# BL808 register map
File version: 0.1
Registers are access not given, no defined reset value unless marked. A register's access mark holds for its fields unless they carry their own. Offsets are from the block's base; [hi:lo] are bit positions.

## CODEC_MISC
Base 0x30020000
0x00 codec_bus_ctrl
  [15:0] rg_pclk_force_on rw
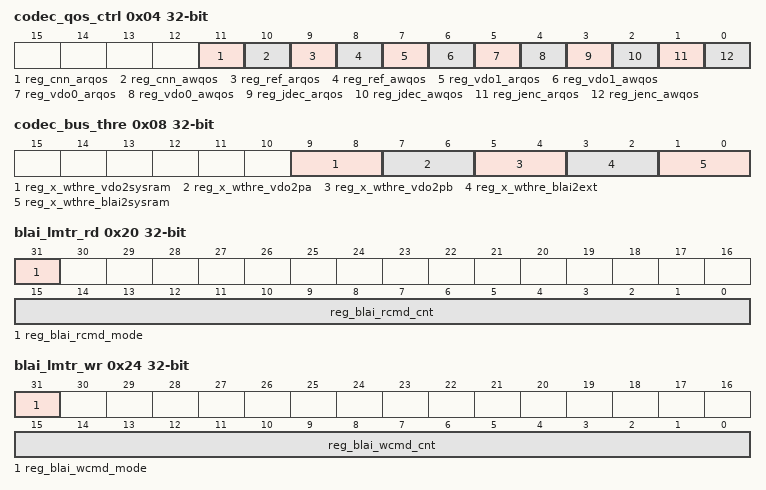
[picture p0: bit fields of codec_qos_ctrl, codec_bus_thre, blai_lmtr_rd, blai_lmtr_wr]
0x04 codec_qos_ctrl
  [11] reg_cnn_arqos rw, [10] reg_cnn_awqos rw, [9] reg_ref_arqos rw, [8] reg_ref_awqos rw, [7] reg_vdo1_arqos rw, [6] reg_vdo1_awqos rw, [5] reg_vdo0_arqos rw, [4] reg_vdo0_awqos rw, [3] reg_jdec_arqos rw, [2] reg_jdec_awqos rw, [1] reg_jenc_arqos rw, [0] reg_jenc_awqos rw
0x08 codec_bus_thre
  [9:8] reg_x_wthre_vdo2sysram rw, [7:6] reg_x_wthre_vdo2pa rw, [5:4] reg_x_wthre_vdo2pb rw, [3:2] reg_x_wthre_blai2ext rw, [1:0] reg_x_wthre_blai2sysram rw
0x20 blai_lmtr_rd
  [31] reg_blai_rcmd_mode rw, [15:0] reg_blai_rcmd_cnt rw
0x24 blai_lmtr_wr
  [31] reg_blai_wcmd_mode rw, [15:0] reg_blai_wcmd_cnt rw
0x28 id_selection
  [0] rg_jenc_id_sel rw
0xFC CODEC_MISC_Dummy rw
  [31:0] dummy_reg

## MIPI
Base 0x3001A000
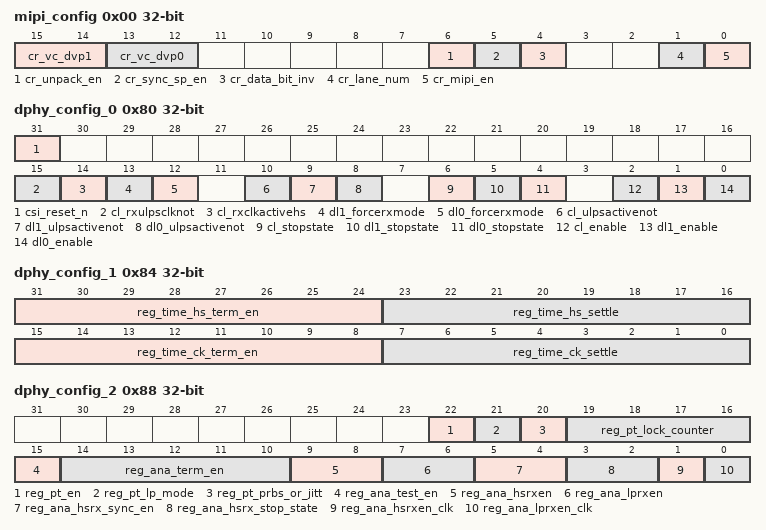
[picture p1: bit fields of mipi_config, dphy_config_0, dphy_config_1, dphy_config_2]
0x00 mipi_config
  [15:14] cr_vc_dvp1 rw, [13:12] cr_vc_dvp0 rw, [6] cr_unpack_en rw, [5] cr_sync_sp_en rw, [4] cr_data_bit_inv rw, [1] cr_lane_num rw, [0] cr_mipi_en rw
0x04 mipi_int_status
  [3:0] mipi_int_status ro
0x08 mipi_int_mask
  [3:0] mipi_int_mask rw
0x0C mipi_int_clear
  [3:0] mipi_int_clear write-once
0x20 gnr_buf_status
  [3:0] st_gnr_fifo_cnt ro
0x24 gnr_buf_rdata ro
  [31:0] gnr_buf_rdata
0x80 dphy_config_0
  [31] csi_reset_n rw, [15] cl_rxulpsclknot ro, [14] cl_rxclkactivehs ro, [13] dl1_forcerxmode rw, [12] dl0_forcerxmode rw, [10] cl_ulpsactivenot ro, [9] dl1_ulpsactivenot ro, [8] dl0_ulpsactivenot ro, [6] cl_stopstate ro, [5] dl1_stopstate ro, [4] dl0_stopstate ro, [2] cl_enable rw, [1] dl1_enable rw, [0] dl0_enable rw
0x84 dphy_config_1 rw
  [31:24] reg_time_hs_term_en, [23:16] reg_time_hs_settle, [15:8] reg_time_ck_term_en, [7:0] reg_time_ck_settle
0x88 dphy_config_2
  [22] reg_pt_en rw, [21] reg_pt_lp_mode rw, [20] reg_pt_prbs_or_jitt rw, [19:16] reg_pt_lock_counter rw, [15] reg_ana_test_en rw, [14:10] reg_ana_term_en rw, [9:8] reg_ana_hsrxen rw, [7:6] reg_ana_lprxen rw, [5:4] reg_ana_hsrx_sync_en rw, [3:2] reg_ana_hsrx_stop_state rw, [1] reg_ana_hsrxen_clk rw, [0] reg_ana_lprxen_clk rw
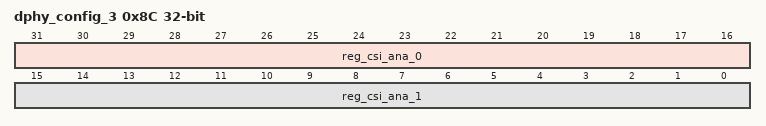
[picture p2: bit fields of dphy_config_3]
0x8C dphy_config_3 rw
  [31:16] reg_csi_ana_0, [15:0] reg_csi_ana_1
0xFC dummy_reg rw
  [31:0] dummy_reg

## OSD_A_BLEND_LAYER0
Base 0x30013000
Same registers: OSD_A_BLEND_LAYER1 0x30013100, OSD_A_BLEND_LAYER2 0x30013200, OSD_A_BLEND_LAYER3 0x30013300, OSD_B_BLEND_LAYER0 0x30014000, OSD_B_BLEND_LAYER1 0x30014100, OSD_DP_BLEND_LAYER0 0x30015000, OSD_DP_BLEND_LAYER1 0x30015100, OSD_DP_BLEND_LAYER2 0x30015200, OSD_DP_BLEND_LAYER3 0x30015300
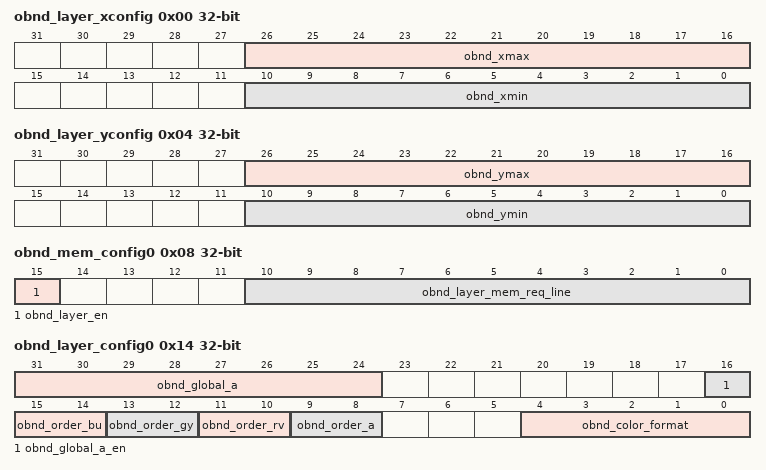
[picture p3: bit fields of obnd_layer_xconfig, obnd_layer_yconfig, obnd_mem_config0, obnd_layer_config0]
0x00 obnd_layer_xconfig
  [26:16] obnd_xmax rw, [10:0] obnd_xmin rw
0x04 obnd_layer_yconfig
  [26:16] obnd_ymax rw, [10:0] obnd_ymin rw
0x08 obnd_mem_config0
  [15] obnd_layer_en rw, [10:0] obnd_layer_mem_req_line rw
0x0C obnd_mem_config1 rw
  [31:0] obnd_mem_addr
0x10 obnd_mem_config2 rw
  [31:0] obnd_mem_dw_cnt
0x14 obnd_layer_config0
  [31:24] obnd_global_a rw, [16] obnd_global_a_en rw, [15:14] obnd_order_bu rw, [13:12] obnd_order_gy rw, [11:10] obnd_order_rv rw, [9:8] obnd_order_a rw, [4:0] obnd_color_format rw
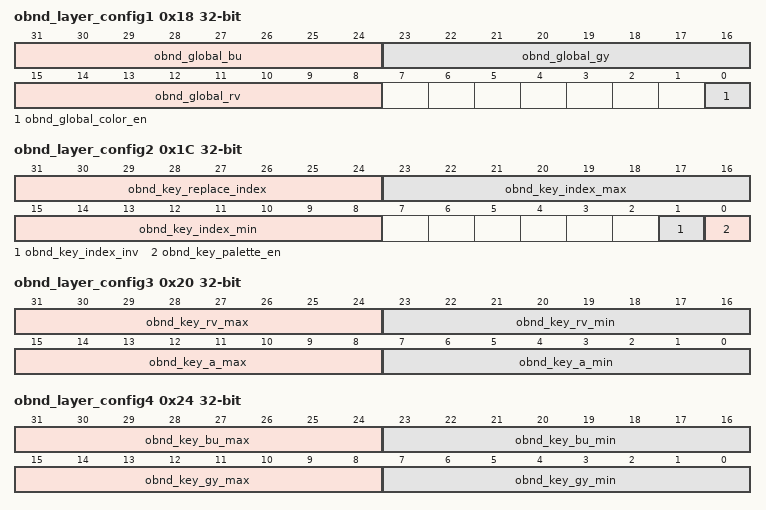
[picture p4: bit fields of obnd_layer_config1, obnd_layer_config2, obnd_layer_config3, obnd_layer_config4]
0x18 obnd_layer_config1
  [31:24] obnd_global_bu rw, [23:16] obnd_global_gy rw, [15:8] obnd_global_rv rw, [0] obnd_global_color_en rw
0x1C obnd_layer_config2
  [31:24] obnd_key_replace_index rw, [23:16] obnd_key_index_max rw, [15:8] obnd_key_index_min rw, [1] obnd_key_index_inv rw, [0] obnd_key_palette_en rw
0x20 obnd_layer_config3 rw
  [31:24] obnd_key_rv_max, [23:16] obnd_key_rv_min, [15:8] obnd_key_a_max, [7:0] obnd_key_a_min
0x24 obnd_layer_config4 rw
  [31:24] obnd_key_bu_max, [23:16] obnd_key_bu_min, [15:8] obnd_key_gy_max, [7:0] obnd_key_gy_min
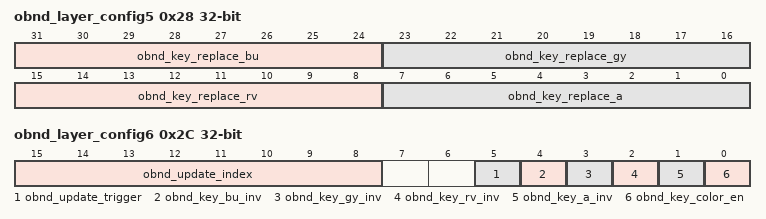
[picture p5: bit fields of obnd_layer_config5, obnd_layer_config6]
0x28 obnd_layer_config5 rw
  [31:24] obnd_key_replace_bu, [23:16] obnd_key_replace_gy, [15:8] obnd_key_replace_rv, [7:0] obnd_key_replace_a
0x2C obnd_layer_config6
  [15:8] obnd_update_index rw, [5] obnd_update_trigger rw, [4] obnd_key_bu_inv rw, [3] obnd_key_gy_inv rw, [2] obnd_key_rv_inv rw, [1] obnd_key_a_inv rw, [0] obnd_key_color_en rw
0x30 obnd_layer_config7 rw
  [31:0] obnd_update_color
